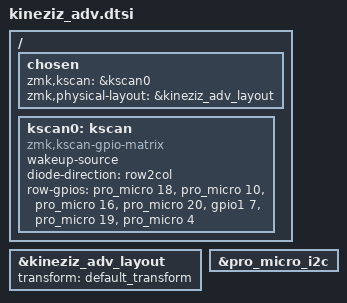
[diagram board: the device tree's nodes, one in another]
/*
 * Copyright (c) 2020 Pete Johanson
 *
 * SPDX-License-Identifier: MIT
 */

#include "kineziz_adv.matrix_transform.dtsi"
#include "kineziz_adv.physical-layout.dtsi"

&kineziz_adv_layout {
    transform = <&default_transform>;
};

/ {
    chosen {
        zmk,kscan = &kscan0;
        zmk,physical-layout = &kineziz_adv_layout;
    };

    kscan0: kscan {
        compatible = "zmk,kscan-gpio-matrix";
        wakeup-source;

        diode-direction = "row2col";
        row-gpios
            = <&pro_micro 18 GPIO_ACTIVE_HIGH>
            , <&pro_micro 10 GPIO_ACTIVE_HIGH>
            , <&pro_micro 16 GPIO_ACTIVE_HIGH>
            , <&pro_micro 20 GPIO_ACTIVE_HIGH>
            , <&gpio1     7  GPIO_ACTIVE_HIGH>
            , <&pro_micro 19 GPIO_ACTIVE_HIGH>
            , <&pro_micro 4  GPIO_ACTIVE_HIGH>
            ;
    };
};

&pro_micro_i2c {
    status = "okay";
};
